# ESP32S31_RADIO register map
Vendor: Espressif; Series: ESP32-S31; File version: 3.52
Registers are 32-bit, read-write, no defined reset value unless marked. A register's access mark holds for its fields unless they carry their own. Offsets are from the block's base; [hi:lo] are bit positions; {n}, {i} and the like mark numbered series.

## BLE_HW_RESOLVING_LIST — Narrow owner for the standalone BLE resolving-list base publication. The complete ESP32-S31 ble_hw.c leaf proves one compressed SRAM pointer word but does not prove that adjacent BTMAC addresses belong to the same logical block.
Base 0x20101880
0x00 BASE_POINTER wo — Complete image equal to the caller-provided SRAM address shifted right by two and truncated to twenty bits.
  [19:0] COMPRESSED_SRAM_POINTER — Bits 0..19 contain address >> 2; bits 20..31 are written as zero.

## BLE_HW_RUNTIME_CONTROL — Sparse BLE hardware status/clear and runtime-configuration view. Complete ESP32-S31 functions prove the array geometry, access directions and exact configuration images. Positional names retain unknown source and field semantics instead of promoting diagnostic strings to hardware truth.
Base 0x20101B00
{0x30+4i} STATUS{i} (i=0..7) ro — Complete status word read once for each of eight sources before optional diagnostic reporting.
  [31:0] PENDING_BITS
{0x50+4i} CLEAR{i} (i=0..7) wo — Paired clear word receiving the complete image 0xFFFFFFFF for each of eight sources.
  [31:0] PENDING_BITS
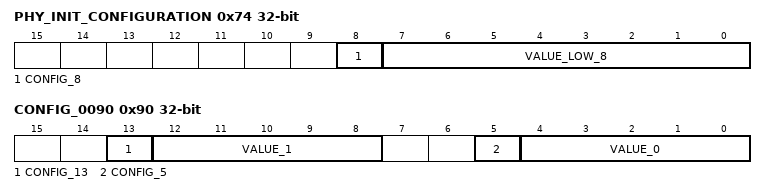
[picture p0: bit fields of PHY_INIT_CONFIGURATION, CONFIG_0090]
0x74 PHY_INIT_CONFIGURATION wo — Complete BLE PHY initialization publishes one runtime-derived low byte together with finite bit 8 as a whole-word image. The byte encoding remains unknown.
  [8] CONFIG_8, [7:0] VALUE_LOW_8
0x78 PHY_INIT_CONFIGURATION_FOLLOWUP wo — Complete BLE PHY initialization writes the finite complete image one immediately after PHY_INIT_CONFIGURATION. The hardware meaning of this ordered follow-up write remains unknown.
  [31:0] IMAGE
0x88 CONFIG_0088 wo — Complete image formed from the low five bits of one controller configuration byte.
  [4:0] VALUE_LOW_5
0x90 CONFIG_0090 wo — Complete image formed from two low-five-bit controller values in bits 0..4 and 8..12 plus finite one bits at positions 5 and 13.
  [13] CONFIG_13, [12:8] VALUE_1, [5] CONFIG_5, [4:0] VALUE_0
0x94 CONFIG_0094 wo — Complete image formed from one controller configuration byte.
  [7:0] VALUE_LOW_8

## BLE_HW_CTE_RING_CONTROL — Direction-finding ring state recovered from complete ESP32-S31 ble_hw_cte.c leaves. Ordinary advertising, scanning and connection link states retain a controller-global disabled-CTE descriptor even when IQ sampling is not requested, so the baseline pointer and ownership fields are part of the minimum standalone BLE controller.
Base 0x2010199C
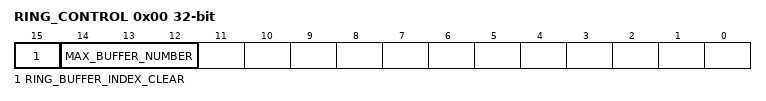
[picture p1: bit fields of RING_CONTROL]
0x00 RING_CONTROL — Reset writes the complete word as zero; independent accessors update the ring index and maximum-buffer fields through halfword RMW operations.
  [15] RING_BUFFER_INDEX_CLEAR — The named clear accessor sets bit 15. The active level and any hardware self-clear behavior remain unproven.
  [14:12] MAX_BUFFER_NUMBER — The setter truncates its argument to three bits and replaces bits 12..14; the getter returns the same field.
{0x4+8i} BUFFER_POINTER{i} (i=0..5) — Compressed controller-SRAM address of one CTE sample-ring descriptor. The setter replaces bits 0..19 and preserves the upper twelve bits.
  [19:0] COMPRESSED_DESCRIPTOR_POINTER — Low-twenty-bit controller-SRAM pointer reconstructed with the fixed 0x2f prefix and four-byte alignment.
{0x8+8i} BUFFER_STATE{i} (i=0..5) — Hardware state paired with one CTE sample-ring descriptor. Only the software-ownership flag is currently assigned.
  [31] SOFTWARE_OWNED — The named owner-clear/set leaves respectively clear and set bit 31; the paired query returns that bit.

## BLE_ISO_SCHEDULER_NOTIFY — Narrow late-feature owner for the command written by two complete ISO-path functions. A positional capability is intentional: the observed write strobe is exact, while the undocumented hardware action is not inferred from the software queue context.
Base 0x20101424
0x00 COMMAND wo — Both observed ISO-path publications write the complete value one.
  [0] TRIGGER — Observed command image is one; hardware self-clear and command meaning remain unknown.
